# C6424_cslr_gpio_003 register map
Vendor: Texas Instruments
Peripheral module from a debugger description file.
Registers are 32-bit, read-write, reset 0x0 unless marked. A register's access mark holds for its fields unless they carry their own. Offsets are as the file gives them; lines under a group give offsets from that group; [hi:lo] are bit positions; {n}, {i} and the like mark numbered series; 'fields as' and 'values as' point back to an identical list; <NAME> marks a mode.

## GPIO — General Purpose Input Output
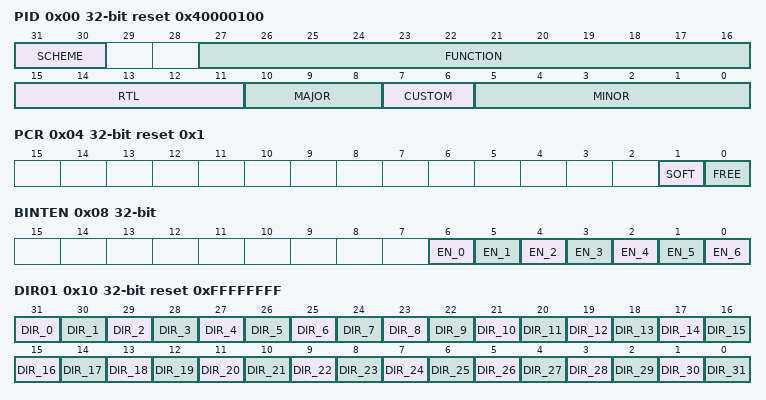
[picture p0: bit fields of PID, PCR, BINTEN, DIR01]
0x00 PID access not given reset 0x40000100 (reset mask 0xF000FFFF) — Peripheral ID Register
  [31:30] SCHEME ro — PID encoding scheme
  [27:16] FUNCTION ro
  [15:11] RTL ro — RTL Identification
  [10:8] MAJOR ro — Major Revision
  [7:6] CUSTOM ro — Custom identification
  [5:0] MINOR ro — Minor Revision
0x04 PCR access not given reset 0x1 — Peripheral Control Register
  [1] SOFT ro — Used along with FREE bit to determine the emulation suspend mode. Conventionally, when FREE bit is cleared, SOFT bit selects the mode. GPIO has FREE = 1, so SOFT bit does not affect functionality
  [0] FREE ro — For GPIO, the FREE bit is fixed at 1, which means GPIO runs free in emulation suspend mode
0x08 BINTEN access not given — GPIO Interrupt Per-Bank Enable Register
  [all] fields
    0=DISABLE; 1=ENABLE
  [6-n] EN_{n} rw (n=0..6) — Per-bank interrupt enable There are 7 banks of 16 GPIOs each. Bit i stands for bank i
0x10 DIR01 reset 0xFFFFFFFF — GPIO Direction Bank 0 and 1 Register
  [all] fields
    0=OUT (Output); 1=IN (Input)
  [31-n] DIR_{n} (n=0..31) — Direction of GPIO bank 0 & 1. Bits 0-15 form bank 0 and bits 16-31 form bank 1
0x14 OUT_DATA01 — GPIO Output Data Bank 0 and 1 Register
  [31] OUT_0 — Output drive state of GPIO bank 0 and 1 Bits 0-15 form bank 0 and bits 16-31 form bank 1 (Ignored when configured as Input)
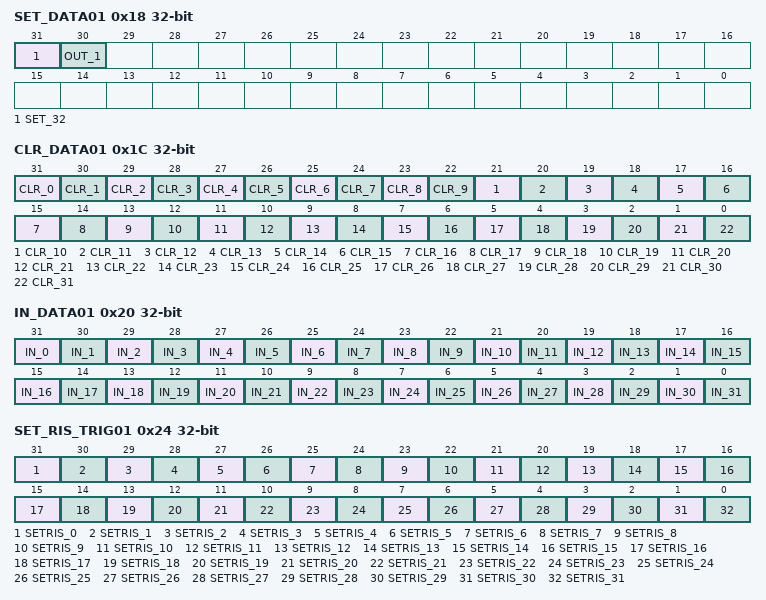
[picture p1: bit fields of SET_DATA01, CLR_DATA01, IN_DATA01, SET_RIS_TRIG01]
0x18 SET_DATA01 — GPIO Set Data 0 and 1 Register
  [31] SET_32 — Set output drive state of GPIO bank 0 and 1 Bits 0-15 form bank 0 and bits 16-31 form bank 1 Writing 1 sets the output drive state of corresponding GPIO. Reading it returns the output drive state
    1=SET (Set output to 1)
  [30] OUT_1 — Output drive state of GPIO bank 0 and 1 Bits 0-15 form bank 0 and bits 16-31 form bank 1 (Ignored when configured as Input)
0x18 SET_DATA01 — GPIO Set Data 0 and 1 Register
  [31] SET_32 — Set output drive state of GPIO bank 0 and 1 Bits 0-15 form bank 0 and bits 16-31 form bank 1 Writing 1 sets the output drive state of corresponding GPIO. Reading it returns the output drive state
    1=SET (Set output to 1)
  [29] OUT_2 — Output drive state of GPIO bank 0 and 1 Bits 0-15 form bank 0 and bits 16-31 form bank 1 (Ignored when configured as Input)
0x18 SET_DATA01 — GPIO Set Data 0 and 1 Register
  [31] SET_32 — Set output drive state of GPIO bank 0 and 1 Bits 0-15 form bank 0 and bits 16-31 form bank 1 Writing 1 sets the output drive state of corresponding GPIO. Reading it returns the output drive state
    1=SET (Set output to 1)
  [28] OUT_3 — Output drive state of GPIO bank 0 and 1 Bits 0-15 form bank 0 and bits 16-31 form bank 1 (Ignored when configured as Input)
0x18 SET_DATA01 — GPIO Set Data 0 and 1 Register
  [31] SET_32 — Set output drive state of GPIO bank 0 and 1 Bits 0-15 form bank 0 and bits 16-31 form bank 1 Writing 1 sets the output drive state of corresponding GPIO. Reading it returns the output drive state
    1=SET (Set output to 1)
  [27] OUT_4 — Output drive state of GPIO bank 0 and 1 Bits 0-15 form bank 0 and bits 16-31 form bank 1 (Ignored when configured as Input)
0x18 SET_DATA01 — GPIO Set Data 0 and 1 Register
  [31] SET_32 — Set output drive state of GPIO bank 0 and 1 Bits 0-15 form bank 0 and bits 16-31 form bank 1 Writing 1 sets the output drive state of corresponding GPIO. Reading it returns the output drive state
    1=SET (Set output to 1)
  [26] OUT_5 — Output drive state of GPIO bank 0 and 1 Bits 0-15 form bank 0 and bits 16-31 form bank 1 (Ignored when configured as Input)
0x18 SET_DATA01 — GPIO Set Data 0 and 1 Register
  [31] SET_32 — Set output drive state of GPIO bank 0 and 1 Bits 0-15 form bank 0 and bits 16-31 form bank 1 Writing 1 sets the output drive state of corresponding GPIO. Reading it returns the output drive state
    1=SET (Set output to 1)
  [25] OUT_6 — Output drive state of GPIO bank 0 and 1 Bits 0-15 form bank 0 and bits 16-31 form bank 1 (Ignored when configured as Input)
0x18 SET_DATA01 — GPIO Set Data 0 and 1 Register
  [31] SET_32 — Set output drive state of GPIO bank 0 and 1 Bits 0-15 form bank 0 and bits 16-31 form bank 1 Writing 1 sets the output drive state of corresponding GPIO. Reading it returns the output drive state
    1=SET (Set output to 1)
  [24] OUT_7 — Output drive state of GPIO bank 0 and 1 Bits 0-15 form bank 0 and bits 16-31 form bank 1 (Ignored when configured as Input)
0x18 SET_DATA01 — GPIO Set Data 0 and 1 Register
  [31] SET_32 — Set output drive state of GPIO bank 0 and 1 Bits 0-15 form bank 0 and bits 16-31 form bank 1 Writing 1 sets the output drive state of corresponding GPIO. Reading it returns the output drive state
    1=SET (Set output to 1)
  [23] OUT_8 — Output drive state of GPIO bank 0 and 1 Bits 0-15 form bank 0 and bits 16-31 form bank 1 (Ignored when configured as Input)
0x18 SET_DATA01 — GPIO Set Data 0 and 1 Register
  [31] SET_32 — Set output drive state of GPIO bank 0 and 1 Bits 0-15 form bank 0 and bits 16-31 form bank 1 Writing 1 sets the output drive state of corresponding GPIO. Reading it returns the output drive state
    1=SET (Set output to 1)
  [22] OUT_9 — Output drive state of GPIO bank 0 and 1 Bits 0-15 form bank 0 and bits 16-31 form bank 1 (Ignored when configured as Input)
0x18 SET_DATA01 — GPIO Set Data 0 and 1 Register
  [31] SET_32 — Set output drive state of GPIO bank 0 and 1 Bits 0-15 form bank 0 and bits 16-31 form bank 1 Writing 1 sets the output drive state of corresponding GPIO. Reading it returns the output drive state
    1=SET (Set output to 1)
  [21] OUT_10 — Output drive state of GPIO bank 0 and 1 Bits 0-15 form bank 0 and bits 16-31 form bank 1 (Ignored when configured as Input)
0x18 SET_DATA01 — GPIO Set Data 0 and 1 Register
  [31] SET_32 — Set output drive state of GPIO bank 0 and 1 Bits 0-15 form bank 0 and bits 16-31 form bank 1 Writing 1 sets the output drive state of corresponding GPIO. Reading it returns the output drive state
    1=SET (Set output to 1)
  [20] OUT_11 — Output drive state of GPIO bank 0 and 1 Bits 0-15 form bank 0 and bits 16-31 form bank 1 (Ignored when configured as Input)
0x18 SET_DATA01 — GPIO Set Data 0 and 1 Register
  [31] SET_32 — Set output drive state of GPIO bank 0 and 1 Bits 0-15 form bank 0 and bits 16-31 form bank 1 Writing 1 sets the output drive state of corresponding GPIO. Reading it returns the output drive state
    1=SET (Set output to 1)
  [19] OUT_12 — Output drive state of GPIO bank 0 and 1 Bits 0-15 form bank 0 and bits 16-31 form bank 1 (Ignored when configured as Input)
0x18 SET_DATA01 — GPIO Set Data 0 and 1 Register
  [31] SET_32 — Set output drive state of GPIO bank 0 and 1 Bits 0-15 form bank 0 and bits 16-31 form bank 1 Writing 1 sets the output drive state of corresponding GPIO. Reading it returns the output drive state
    1=SET (Set output to 1)
  [18] OUT_13 — Output drive state of GPIO bank 0 and 1 Bits 0-15 form bank 0 and bits 16-31 form bank 1 (Ignored when configured as Input)
0x18 SET_DATA01 — GPIO Set Data 0 and 1 Register
  [31] SET_32 — Set output drive state of GPIO bank 0 and 1 Bits 0-15 form bank 0 and bits 16-31 form bank 1 Writing 1 sets the output drive state of corresponding GPIO. Reading it returns the output drive state
    1=SET (Set output to 1)
  [17] OUT_14 — Output drive state of GPIO bank 0 and 1 Bits 0-15 form bank 0 and bits 16-31 form bank 1 (Ignored when configured as Input)
0x18 SET_DATA01 — GPIO Set Data 0 and 1 Register
  [31] SET_32 — Set output drive state of GPIO bank 0 and 1 Bits 0-15 form bank 0 and bits 16-31 form bank 1 Writing 1 sets the output drive state of corresponding GPIO. Reading it returns the output drive state
    1=SET (Set output to 1)
  [16] OUT_15 — Output drive state of GPIO bank 0 and 1 Bits 0-15 form bank 0 and bits 16-31 form bank 1 (Ignored when configured as Input)
0x18 SET_DATA01 — GPIO Set Data 0 and 1 Register
  [31] SET_32 — Set output drive state of GPIO bank 0 and 1 Bits 0-15 form bank 0 and bits 16-31 form bank 1 Writing 1 sets the output drive state of corresponding GPIO. Reading it returns the output drive state
    1=SET (Set output to 1)
  [15] OUT_16 — Output drive state of GPIO bank 0 and 1 Bits 0-15 form bank 0 and bits 16-31 form bank 1 (Ignored when configured as Input)
0x18 SET_DATA01 — GPIO Set Data 0 and 1 Register
  [31] SET_32 — Set output drive state of GPIO bank 0 and 1 Bits 0-15 form bank 0 and bits 16-31 form bank 1 Writing 1 sets the output drive state of corresponding GPIO. Reading it returns the output drive state
    1=SET (Set output to 1)
  [14] OUT_17 — Output drive state of GPIO bank 0 and 1 Bits 0-15 form bank 0 and bits 16-31 form bank 1 (Ignored when configured as Input)
0x18 SET_DATA01 — GPIO Set Data 0 and 1 Register
  [31] SET_32 — Set output drive state of GPIO bank 0 and 1 Bits 0-15 form bank 0 and bits 16-31 form bank 1 Writing 1 sets the output drive state of corresponding GPIO. Reading it returns the output drive state
    1=SET (Set output to 1)
  [13] OUT_18 — Output drive state of GPIO bank 0 and 1 Bits 0-15 form bank 0 and bits 16-31 form bank 1 (Ignored when configured as Input)
0x18 SET_DATA01 — GPIO Set Data 0 and 1 Register
  [31] SET_32 — Set output drive state of GPIO bank 0 and 1 Bits 0-15 form bank 0 and bits 16-31 form bank 1 Writing 1 sets the output drive state of corresponding GPIO. Reading it returns the output drive state
    1=SET (Set output to 1)
  [12] OUT_19 — Output drive state of GPIO bank 0 and 1 Bits 0-15 form bank 0 and bits 16-31 form bank 1 (Ignored when configured as Input)
0x18 SET_DATA01 — GPIO Set Data 0 and 1 Register
  [31] SET_32 — Set output drive state of GPIO bank 0 and 1 Bits 0-15 form bank 0 and bits 16-31 form bank 1 Writing 1 sets the output drive state of corresponding GPIO. Reading it returns the output drive state
    1=SET (Set output to 1)
  [11] OUT_20 — Output drive state of GPIO bank 0 and 1 Bits 0-15 form bank 0 and bits 16-31 form bank 1 (Ignored when configured as Input)
0x18 SET_DATA01 — GPIO Set Data 0 and 1 Register
  [31] SET_32 — Set output drive state of GPIO bank 0 and 1 Bits 0-15 form bank 0 and bits 16-31 form bank 1 Writing 1 sets the output drive state of corresponding GPIO. Reading it returns the output drive state
    1=SET (Set output to 1)
  [10] OUT_21 — Output drive state of GPIO bank 0 and 1 Bits 0-15 form bank 0 and bits 16-31 form bank 1 (Ignored when configured as Input)
0x18 SET_DATA01 — GPIO Set Data 0 and 1 Register
  [31] SET_32 — Set output drive state of GPIO bank 0 and 1 Bits 0-15 form bank 0 and bits 16-31 form bank 1 Writing 1 sets the output drive state of corresponding GPIO. Reading it returns the output drive state
    1=SET (Set output to 1)
  [9] OUT_22 — Output drive state of GPIO bank 0 and 1 Bits 0-15 form bank 0 and bits 16-31 form bank 1 (Ignored when configured as Input)
0x18 SET_DATA01 — GPIO Set Data 0 and 1 Register
  [31] SET_32 — Set output drive state of GPIO bank 0 and 1 Bits 0-15 form bank 0 and bits 16-31 form bank 1 Writing 1 sets the output drive state of corresponding GPIO. Reading it returns the output drive state
    1=SET (Set output to 1)
  [8] OUT_23 — Output drive state of GPIO bank 0 and 1 Bits 0-15 form bank 0 and bits 16-31 form bank 1 (Ignored when configured as Input)
0x18 SET_DATA01 — GPIO Set Data 0 and 1 Register
  [31] SET_32 — Set output drive state of GPIO bank 0 and 1 Bits 0-15 form bank 0 and bits 16-31 form bank 1 Writing 1 sets the output drive state of corresponding GPIO. Reading it returns the output drive state
    1=SET (Set output to 1)
  [7] OUT_24 — Output drive state of GPIO bank 0 and 1 Bits 0-15 form bank 0 and bits 16-31 form bank 1 (Ignored when configured as Input)
0x18 SET_DATA01 — GPIO Set Data 0 and 1 Register
  [31] SET_32 — Set output drive state of GPIO bank 0 and 1 Bits 0-15 form bank 0 and bits 16-31 form bank 1 Writing 1 sets the output drive state of corresponding GPIO. Reading it returns the output drive state
    1=SET (Set output to 1)
  [6] OUT_25 — Output drive state of GPIO bank 0 and 1 Bits 0-15 form bank 0 and bits 16-31 form bank 1 (Ignored when configured as Input)
0x18 SET_DATA01 — GPIO Set Data 0 and 1 Register
  [31] SET_32 — Set output drive state of GPIO bank 0 and 1 Bits 0-15 form bank 0 and bits 16-31 form bank 1 Writing 1 sets the output drive state of corresponding GPIO. Reading it returns the output drive state
    1=SET (Set output to 1)
  [5] OUT_26 — Output drive state of GPIO bank 0 and 1 Bits 0-15 form bank 0 and bits 16-31 form bank 1 (Ignored when configured as Input)
0x18 SET_DATA01 — GPIO Set Data 0 and 1 Register
  [31] SET_32 — Set output drive state of GPIO bank 0 and 1 Bits 0-15 form bank 0 and bits 16-31 form bank 1 Writing 1 sets the output drive state of corresponding GPIO. Reading it returns the output drive state
    1=SET (Set output to 1)
  [4] OUT_27 — Output drive state of GPIO bank 0 and 1 Bits 0-15 form bank 0 and bits 16-31 form bank 1 (Ignored when configured as Input)
0x18 SET_DATA01 — GPIO Set Data 0 and 1 Register
  [31] SET_32 — Set output drive state of GPIO bank 0 and 1 Bits 0-15 form bank 0 and bits 16-31 form bank 1 Writing 1 sets the output drive state of corresponding GPIO. Reading it returns the output drive state
    1=SET (Set output to 1)
  [3] OUT_28 — Output drive state of GPIO bank 0 and 1 Bits 0-15 form bank 0 and bits 16-31 form bank 1 (Ignored when configured as Input)
0x18 SET_DATA01 — GPIO Set Data 0 and 1 Register
  [31] SET_32 — Set output drive state of GPIO bank 0 and 1 Bits 0-15 form bank 0 and bits 16-31 form bank 1 Writing 1 sets the output drive state of corresponding GPIO. Reading it returns the output drive state
    1=SET (Set output to 1)
  [2] OUT_29 — Output drive state of GPIO bank 0 and 1 Bits 0-15 form bank 0 and bits 16-31 form bank 1 (Ignored when configured as Input)
0x18 SET_DATA01 — GPIO Set Data 0 and 1 Register
  [31] SET_32 — Set output drive state of GPIO bank 0 and 1 Bits 0-15 form bank 0 and bits 16-31 form bank 1 Writing 1 sets the output drive state of corresponding GPIO. Reading it returns the output drive state
    1=SET (Set output to 1)
  [1] OUT_30 — Output drive state of GPIO bank 0 and 1 Bits 0-15 form bank 0 and bits 16-31 form bank 1 (Ignored when configured as Input)
0x18 SET_DATA01 — GPIO Set Data 0 and 1 Register
  [31] SET_32 — Set output drive state of GPIO bank 0 and 1 Bits 0-15 form bank 0 and bits 16-31 form bank 1 Writing 1 sets the output drive state of corresponding GPIO. Reading it returns the output drive state
    1=SET (Set output to 1)
  [0] OUT_31 — Output drive state of GPIO bank 0 and 1 Bits 0-15 form bank 0 and bits 16-31 form bank 1 (Ignored when configured as Input)
0x18 SET_DATA01 — GPIO Set Data 0 and 1 Register
  [31] SET_32 — Set output drive state of GPIO bank 0 and 1 Bits 0-15 form bank 0 and bits 16-31 form bank 1 Writing 1 sets the output drive state of corresponding GPIO. Reading it returns the output drive state
    1=SET (Set output to 1)
0x1C CLR_DATA01 — GPIO Clear Data Bank 0 and 1 Register
  [all] fields
    1=CLR (Clear output to 0)
  [31-n] CLR_{n} (n=0..31) — Clear output drive state of GPIO bank 0 and 1 Bits 0-15 form bank 0 and bits 16-31 form bank 1 Writing 1 clears the output drive state of corresponding GPIO. Reading it returns the output drive state
0x20 IN_DATA01 ro — GPIO Input Data Bank 0 and 1 Register
  [all] fields
    1=SET; 0=CLR
  [31-n] IN_{n} (n=0..31) — Status of GPIO bank 0 and 1 Bits 0-15 form bank 0 and bits 16-31 form bank 1
0x24 SET_RIS_TRIG01 — GPIO Set Rising Edge Interrupt Bank 0 and 1 Register
  [all] fields
    1=ENABLE
  [31-n] SETRIS_{n} (n=0..31) — Enable Rising edge interrupt detection for GPIO bank 0 and 1 Bits 0-15 form bank 0 and bits 16-31 form bank 1 Reading returns state of RIS_TRG
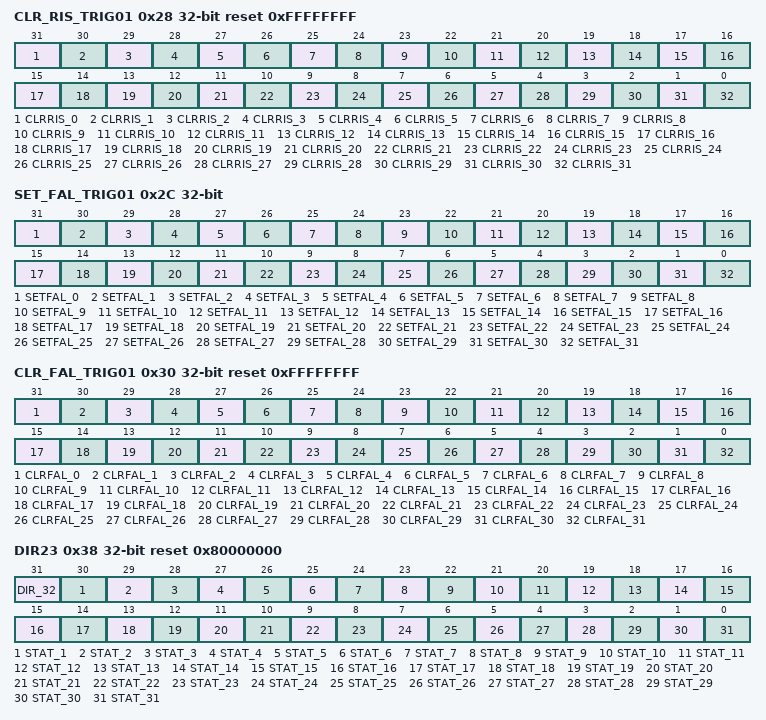
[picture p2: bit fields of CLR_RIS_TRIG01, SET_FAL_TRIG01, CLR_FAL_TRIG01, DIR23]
0x28 CLR_RIS_TRIG01 reset 0xFFFFFFFF — GPIO Clear Rising Edge Interrupt Bank 0 and 1 Register
  [all] fields
    0=DISABLE
  [31-n] CLRRIS_{n} (n=0..31) — Disable Rising edge interrupt detection for GPIO bank 0 and 1 Bits 0-15 form bank 0 and bits 16-31 form bank 1 Reading returns complement state of RIS_TRG
0x2C SET_FAL_TRIG01 — GPIO Set Falling Edge Interrupt Bank 0 and 1 Register
  [all] fields
    1=ENABLE
  [31-n] SETFAL_{n} (n=0..31) — Enable Falling edge interrupt detection for GPIO bank 0 and 1 Bits 0-15 form bank 0 and bits 16-31 form bank 1 Reading returns state of FAL_TRG
0x30 CLR_FAL_TRIG01 reset 0xFFFFFFFF — GPIO Clear Falling Edge Interrupt Bank 0 and 1 Register
  [all] fields
    0=DISABLE
  [31-n] CLRFAL_{n} (n=0..31) — Disable Falling edge interrupt detection for GPIO bank 0 and bank 1 Bits 0-15 form bank 0 and bits 16-31 form bank 0+1 Reading returns complement state of FAL_TRG
0x34 INTSTAT01 — GPIO Interrupt Status Bank 0 and 1 Register
  [31] STAT_0 — Status of GPIO bank 0 and 1 Bits 0-15 form bank 0 and bits 16-31 form bank 1 Reading 0: Interrupt didn't occur Reading 1: Interrupt occurred Writing 1: Clear interrupt status
0x38 DIR23 reset 0x80000000 — GPIO Direction Bank 2 and 3 Register
  [31] DIR_32 — Direction of GPIO bank 2 & 3. Bits 0-15 form bank 2 and bits 16-31 form bank 3
    0=OUT (Output); 1=IN (Input)
  [31-n] STAT_{n} (n=1..31) — Status of GPIO bank 0 and 1 Bits 0-15 form bank 0 and bits 16-31 form bank 1 Reading 0: Interrupt didn't occur Reading 1: Interrupt occurred Writing 1: Clear interrupt status
0x3C OUT_DATA23 — GPIO Output Data Bank 2 and 3 Register
  [31] OUT_0 — Output drive state of GPIO bank 2 and 3 Bits 0-15 form bank 2 and bits 16-31 form bank 3 (Ignored when configured as Input)
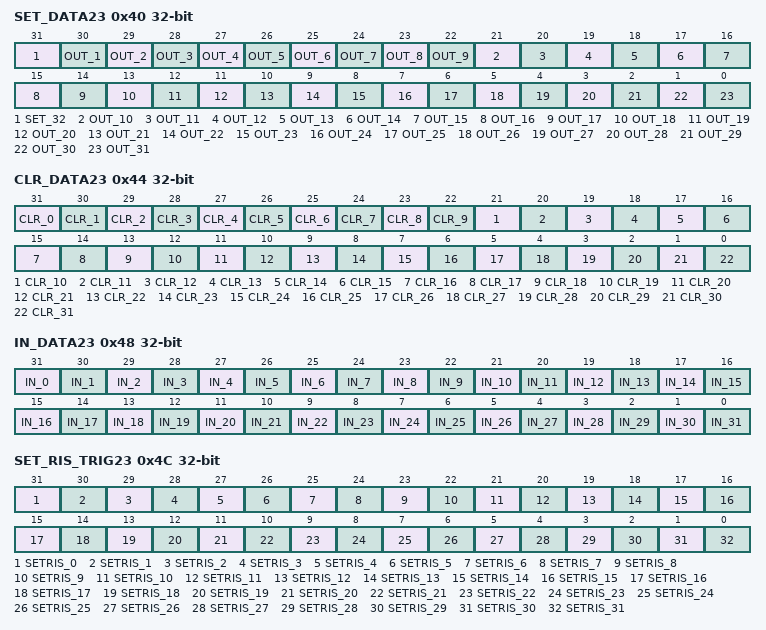
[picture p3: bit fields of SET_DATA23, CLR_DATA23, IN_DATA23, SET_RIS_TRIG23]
0x40 SET_DATA23 — GPIO Set Data 0 and 1 Register
  [31] SET_32 — Set output drive state of GPIO bank 2 and 3 Bits 0-15 form bank 2 and bits 16-31 form bank 3 Writing 1 sets the output drive state of corresponding GPIO. Reading it returns the output drive state
    1=SET (Set output to 1)
  [31-n] OUT_{n} (n=1..31) — Output drive state of GPIO bank 2 and 3 Bits 0-15 form bank 2 and bits 16-31 form bank 3 (Ignored when configured as Input)
0x44 CLR_DATA23 — GPIO Clear Data Bank 2 and 3 Register
  [all] fields
    1=CLR (Clear output to 0)
  [31-n] CLR_{n} (n=0..31) — Clear output drive state of GPIO bank 2 and 3 Bits 0-15 form bank 2 and bits 16-31 form bank 3 Writing 1 clears the output drive state of corresponding GPIO. Reading it returns the output drive state
0x48 IN_DATA23 ro — GPIO Input Data Bank 2 and 3 Register
  [all] fields
    1=SET; 0=CLR
  [31-n] IN_{n} (n=0..31) — Status of GPIO bank 2 and 3 Bits 0-15 form bank 2 and bits 16-31 form bank 3
0x4C SET_RIS_TRIG23 — GPIO Set Rising Edge Interrupt Bank 2 and 3 Register
  [all] fields
    1=ENABLE
  [31-n] SETRIS_{n} (n=0..31) — Enable Rising edge interrupt detection for GPIO bank 2 and 3 Bits 0-15 form bank 2 and bits 16-31 form bank 3 Reading returns state of RIS_TRG
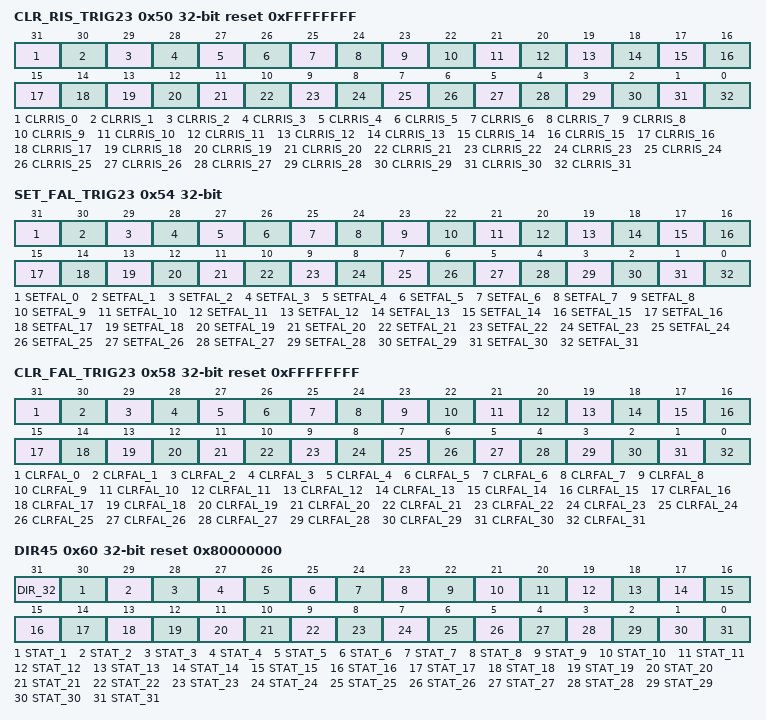
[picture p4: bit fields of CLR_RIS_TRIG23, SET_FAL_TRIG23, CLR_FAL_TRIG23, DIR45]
0x50 CLR_RIS_TRIG23 reset 0xFFFFFFFF — GPIO Clear Rising Edge Interrupt Bank 2 and 3 Register
  [all] fields
    0=DISABLE
  [31-n] CLRRIS_{n} (n=0..31) — Disable Rising edge interrupt detection for GPIO bank 2 and 3 Bits 0-15 form bank 2 and bits 16-31 form bank 3 Reading returns complement state of RIS_TRG
0x54 SET_FAL_TRIG23 — GPIO Set Falling Edge Interrupt Bank 2 and 3 Register
  [all] fields
    1=ENABLE
  [31-n] SETFAL_{n} (n=0..31) — Enable Falling edge interrupt detection for GPIO bank 2 and 3 Bits 0-15 form bank 2 and bits 16-31 form bank 3 Reading returns state of FAL_TRG
0x58 CLR_FAL_TRIG23 reset 0xFFFFFFFF — GPIO Clear Falling Edge Interrupt Bank 2 and 3 Register
  [all] fields
    0=DISABLE
  [31-n] CLRFAL_{n} (n=0..31) — Disable Falling edge interrupt detection for GPIO bank 0 and bank 1 Bits 0-15 form bank 2 and bits 16-31 form bank 3 Reading returns complement state of FAL_TRG
0x5C INTSTAT23 — GPIO Interrupt Status Bank 2 and 3 Register
  [31] STAT_0 — Status of GPIO bank 2 and 3 Bits 0-15 form bank 2 and bits 16-31 form bank 3 Reading 0: Interrupt didn't occur Reading 1: Interrupt occurred Writing 1: Clear interrupt status
0x60 DIR45 reset 0x80000000 — GPIO Direction Bank 4 and 5 Register
  [31] DIR_32 — Direction of GPIO bank 4 and 5. Bits 0-15 form bank 4 and bits 16-31 form bank 5
    0=OUT (Output); 1=IN (Input)
  [31-n] STAT_{n} (n=1..31) — Status of GPIO bank 2 and 3 Bits 0-15 form bank 2 and bits 16-31 form bank 3 Reading 0: Interrupt didn't occur Reading 1: Interrupt occurred Writing 1: Clear interrupt status
0x64 OUT_DATA45 — GPIO Output Data Bank 4 and 5 Register
  [31] OUT_0 — Output drive state of GPIO bank 4 and 5 Bits 0-15 form bank 4 and bits 16-31 form bank 5 (Ignored when configured as Input)
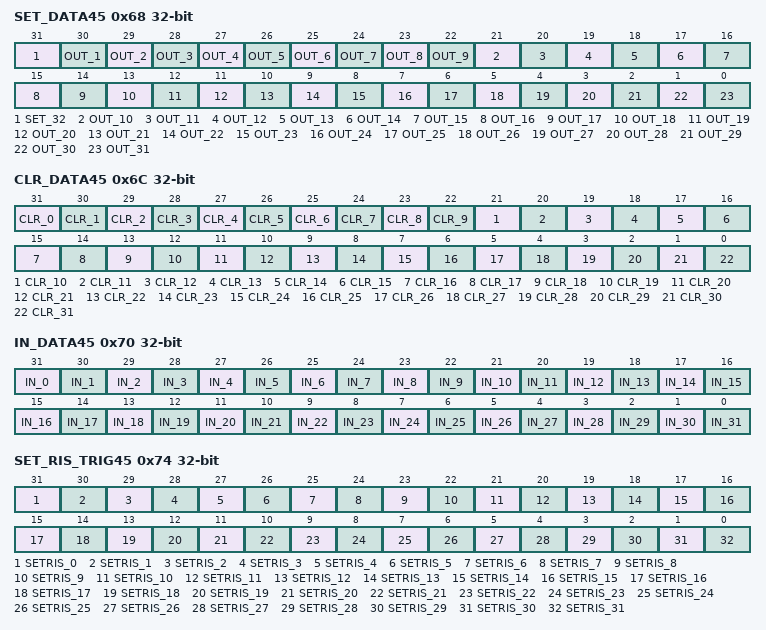
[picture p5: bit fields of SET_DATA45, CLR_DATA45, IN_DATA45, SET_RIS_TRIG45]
0x68 SET_DATA45 — GPIO Set Data 0 and 1 Register
  [31] SET_32 — Set output drive state of GPIO bank 4 and 5 Bits 0-15 form bank 4 and bits 16-31 form bank 5 Writing 1 sets the output drive state of corresponding GPIO. Reading it returns the output drive state
    1=SET (Set output to 1)
  [31-n] OUT_{n} (n=1..31) — Output drive state of GPIO bank 4 and 5 Bits 0-15 form bank 4 and bits 16-31 form bank 5 (Ignored when configured as Input)
0x6C CLR_DATA45 — GPIO Clear Data Bank 4 and 5 Register
  [all] fields
    1=CLR (Clear output to 0)
  [31-n] CLR_{n} (n=0..31) — Clear output drive state of GPIO bank 4 and 5 Bits 0-15 form bank 4 and bits 16-31 form bank 5 Writing 1 clears the output drive state of corresponding GPIO. Reading it returns the output drive state
0x70 IN_DATA45 ro — GPIO Input Data Bank 4 and 5 Register
  [all] fields
    1=SET; 0=CLR
  [31-n] IN_{n} (n=0..31) — Status of GPIO bank 4 and 5 Bits 0-15 form bank 4 and bits 16-31 form bank 5
0x74 SET_RIS_TRIG45 — GPIO Set Rising Edge Interrupt Bank 4 and 5 Register
  [all] fields
    1=ENABLE
  [31-n] SETRIS_{n} (n=0..31) — Enable Rising edge interrupt detection for GPIO bank 4 and 5 Bits 0-15 form bank 4 and bits 16-31 form bank 5 Reading returns state of RIS_TRG
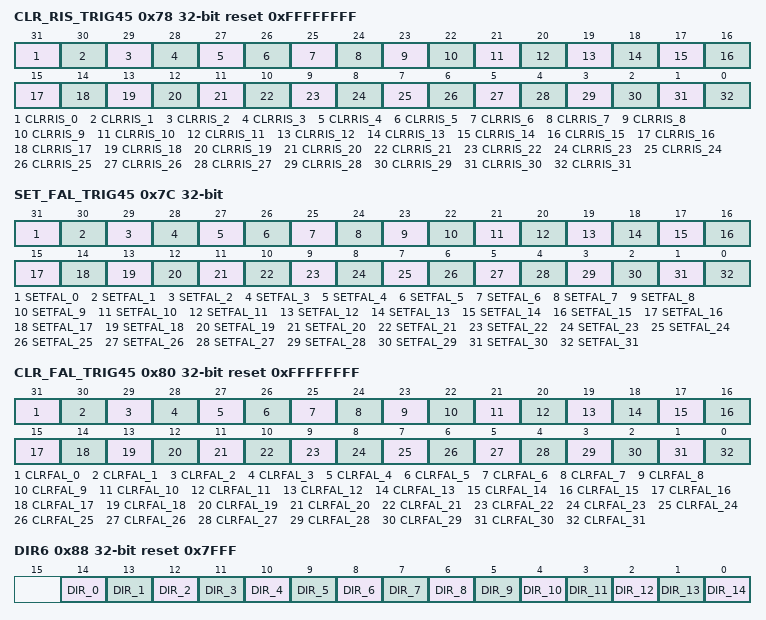
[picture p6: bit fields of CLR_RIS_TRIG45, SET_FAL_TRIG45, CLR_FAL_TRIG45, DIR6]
0x78 CLR_RIS_TRIG45 reset 0xFFFFFFFF — GPIO Clear Rising Edge Interrupt Bank 4 and 5 Register
  [all] fields
    0=DISABLE
  [31-n] CLRRIS_{n} (n=0..31) — Disable Rising edge interrupt detection for GPIO bank 4 and 5 Bits 0-15 form bank 4 and bits 16-31 form bank 5 Reading returns complement state of RIS_TRG
0x7C SET_FAL_TRIG45 — GPIO Set Falling Edge Interrupt Bank 4 and 5 Register
  [all] fields
    1=ENABLE
  [31-n] SETFAL_{n} (n=0..31) — Enable Falling edge interrupt detection for GPIO bank 4 and 5 Bits 0-15 form bank 4 and bits 16-31 form bank 5 Reading returns state of FAL_TRG
0x80 CLR_FAL_TRIG45 reset 0xFFFFFFFF — GPIO Clear Falling Edge Interrupt Bank 4 and 5 Register
  fields as CLR_FAL_TRIG01
0x84 INTSTAT45 — GPIO Interrupt Status Bank 4 and 5 Register
  [31] STAT_0 — Status of GPIO bank 4 and 5 Bits 0-15 form bank 4 and bits 16-31 form bank 5 Reading 0: Interrupt didn't occur Reading 1: Interrupt occurred Writing 1: Clear interrupt status
0x88 DIR6 access not given reset 0x7FFF — GPIO Bank 6 Direction Register
  [all] fields
    0=OUT (Output); 1=IN (Input)
  [14-n] DIR_{n} rw (n=0..14) — Direction of GPIO bank 6 bit 0...14 Bits 0-14 form bank 6.
0x8C OUT_DATA6 access not given — GPIO Bank 6 Output Data Register
  [14] OUT_0 rw — Output drive state of GPIO bank 6 bit 0...14 (Ignored when configured as Input)
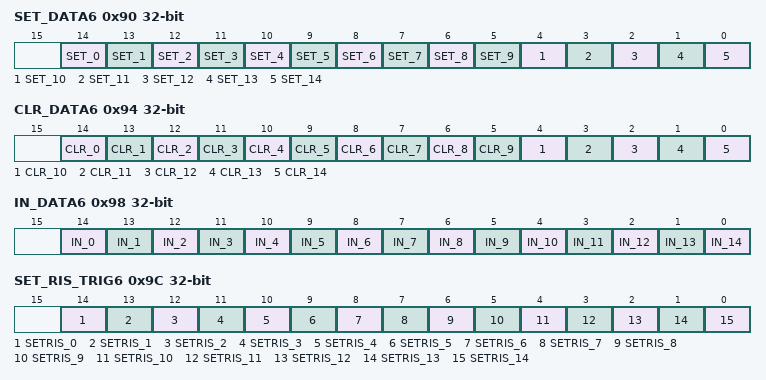
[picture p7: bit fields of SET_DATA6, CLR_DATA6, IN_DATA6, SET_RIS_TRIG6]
0x90 SET_DATA6 access not given — GPIO Bank 6 Set Data Register
  [13] OUT_1 rw — Output drive state of GPIO bank 6 bit 0...14 (Ignored when configured as Input)
0x90 SET_DATA6 access not given — GPIO Bank 6 Set Data Register
  [12] OUT_2 rw — Output drive state of GPIO bank 6 bit 0...14 (Ignored when configured as Input)
0x90 SET_DATA6 access not given — GPIO Bank 6 Set Data Register
  [11] OUT_3 rw — Output drive state of GPIO bank 6 bit 0...14 (Ignored when configured as Input)
0x90 SET_DATA6 access not given — GPIO Bank 6 Set Data Register
  [10] OUT_4 rw — Output drive state of GPIO bank 6 bit 0...14 (Ignored when configured as Input)
0x90 SET_DATA6 access not given — GPIO Bank 6 Set Data Register
  [9] OUT_5 rw — Output drive state of GPIO bank 6 bit 0...14 (Ignored when configured as Input)
0x90 SET_DATA6 access not given — GPIO Bank 6 Set Data Register
  [8] OUT_6 rw — Output drive state of GPIO bank 6 bit 0...14 (Ignored when configured as Input)
0x90 SET_DATA6 access not given — GPIO Bank 6 Set Data Register
  [7] OUT_7 rw — Output drive state of GPIO bank 6 bit 0...14 (Ignored when configured as Input)
0x90 SET_DATA6 access not given — GPIO Bank 6 Set Data Register
  [6] OUT_8 rw — Output drive state of GPIO bank 6 bit 0...14 (Ignored when configured as Input)
0x90 SET_DATA6 access not given — GPIO Bank 6 Set Data Register
  [5] OUT_9 rw — Output drive state of GPIO bank 6 bit 0...14 (Ignored when configured as Input)
0x90 SET_DATA6 access not given — GPIO Bank 6 Set Data Register
  [4] OUT_10 rw — Output drive state of GPIO bank 6 bit 0...14 (Ignored when configured as Input)
0x90 SET_DATA6 access not given — GPIO Bank 6 Set Data Register
  [3] OUT_11 rw — Output drive state of GPIO bank 6 bit 0...14 (Ignored when configured as Input)
0x90 SET_DATA6 access not given — GPIO Bank 6 Set Data Register
  [2] OUT_12 rw — Output drive state of GPIO bank 6 bit 0...14 (Ignored when configured as Input)
0x90 SET_DATA6 access not given — GPIO Bank 6 Set Data Register
  [1] OUT_13 rw — Output drive state of GPIO bank 6 bit 0...14 (Ignored when configured as Input)
0x90 SET_DATA6 access not given — GPIO Bank 6 Set Data Register
  [0] OUT_14 rw — Output drive state of GPIO bank 6 bit 0...14 (Ignored when configured as Input)
0x90 SET_DATA6 access not given — GPIO Bank 6 Set Data Register
  [all] fields
    1=SET (Set output to 1)
  [14-n] SET_{n} rw (n=0..14) — Set output drive state of GPIO bank 6 bit 0...14 Writing 1 sets the output drive state of corresponding GPIO. Reading it returns the output drive state
0x94 CLR_DATA6 access not given — GPIO Bank 6 Clear Data Register
  [all] fields
    1=CLR (Clear output to 0)
  [14-n] CLR_{n} rw (n=0..14) — Clear output drive state of GPIO bank 6 bit 0...14 Writing 1 clears the output drive state of corresponding GPIO. Reading it returns the output drive state
0x98 IN_DATA6 access not given — GPIO Bank 6 Input Data Register
  [all] fields
    1=SET; 0=CLR
  [14-n] IN_{n} ro (n=0..14) — Status of GPIO bank 6 bit 0...14
0x9C SET_RIS_TRIG6 access not given — GPIO Bank 6 Set Rising Edge Interrupt Register
  [all] fields
    1=ENABLE
  [14-n] SETRIS_{n} rw (n=0..14) — Enable Rising edge interrupt detection for GPIO bank 6 bit 0...14 Reading returns state of RIS_TRG
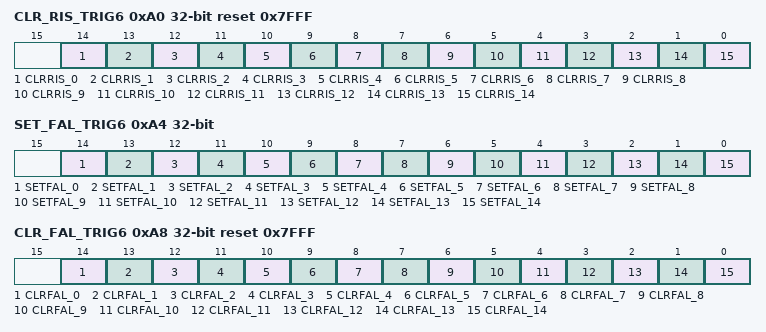
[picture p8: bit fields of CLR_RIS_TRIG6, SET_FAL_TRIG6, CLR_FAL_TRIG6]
0xA0 CLR_RIS_TRIG6 access not given reset 0x7FFF — GPIO Bank 6 Clear Rising Edge Interrupt Register
  [all] fields
    0=DISABLE
  [14-n] CLRRIS_{n} rw (n=0..14) — Disable Rising edge interrupt detection for GPIO bank 6 bit 0...14 Reading returns complement state of RIS_TRG
0xA4 SET_FAL_TRIG6 access not given — GPIO Bank 6 Set Falling Edge Interrupt Register
  [all] fields
    1=ENABLE
  [14-n] SETFAL_{n} rw (n=0..14) — Enable Falling edge interrupt detection for GPIO bank 6 bit 0...14 Reading returns state of FAL_TRG
0xA4 SET_FAL_TRIG6 access not given — GPIO Bank 6 Set Falling Edge Interrupt Register
  fields as SET_FAL_TRIG6
0xA8 CLR_FAL_TRIG6 access not given reset 0x7FFF — GPIO Bank 6 Clear Falling Edge Interrupt Register
  [all] fields
    0=DISABLE
  [14-n] CLRFAL_{n} rw (n=0..14) — Disable Falling edge interrupt detection for GPIO bank 6 bit 0...14 Reading returns complement state of FAL_TRG
